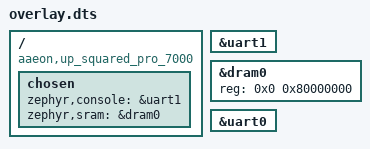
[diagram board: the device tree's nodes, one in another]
/ {
	compatible = "aaeon,up_squared_pro_7000";
	chosen {
		zephyr,console = &uart1;
		zephyr,sram = &dram0;
	};
};
&uart1{
	status = "okay";
};
&dram0{
	reg = < 0x0 0x80000000 >;
};
&uart0{
	status = "okay";
};
